# nrf54h20_enga_application register map
Vendor: Nordic Semiconductor; Series: nRF54h; File version: 1
CPU: CM33 r0p4, little endian, MPU, FPU, 3 interrupt priority bits, 480 interrupts, 4 SAU regions
Registers are 32-bit, read-write, reset 0x0 unless marked. A register's access mark holds for its fields unless they carry their own. Offsets are from the block's base; [hi:lo] are bit positions; lines under a group give offsets from that group; {n}, {i} and the like mark numbered series; 'fields as' and 'values as' point back to an identical list.

## UICR_NS — User information configuration registers
Base 0x0FFF8000
{0x0+8i} MEM[{i}] (i=0..15) group — Unspecified
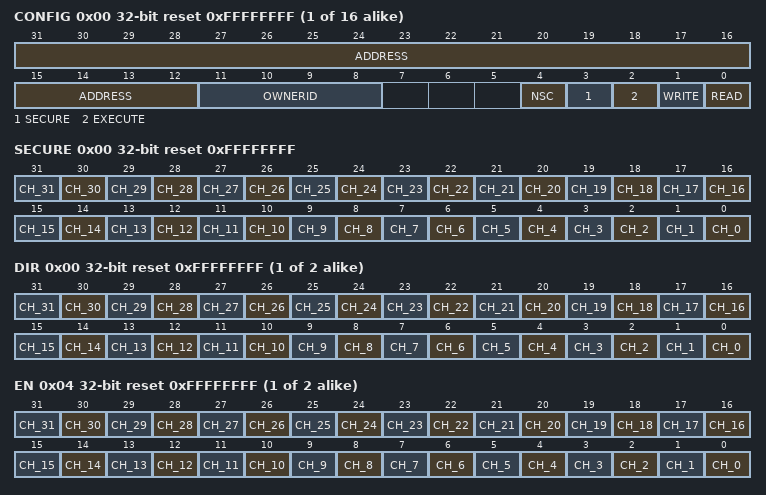
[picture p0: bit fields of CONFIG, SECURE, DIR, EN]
  0x00 CONFIG reset 0xFFFFFFFF — Description cluster: Memory configuration of the memory region
    [31:12] ADDRESS — Memory region start address, bits [31:12]
    [11:8] OWNERID — Memory owner identification
    [4] NSC
      1=Disabled (Memory region is not non-secure callable); 0=Enabled (Memory region is non-secure callable)
    [3] SECURE
      1=Secure (Non-secure access to MEM[n] is not allowed); 0=Non-secure access to MEM[n] is allowed
    [2] EXECUTE
      1=NotAllowed (SW execution from MEM[n] is not allowed); 0=Allowed (SW execution from MEM[n] is allowed)
    [1] WRITE
      1=NotAllowed (Write access to MEM[n] is not allowed); 0=Allowed (Write access to MEM[n] is allowed)
    [0] READ
      1=NotAllowed (Read access to MEM[n] is not allowed); 0=Allowed (Read access to MEM[n] is allowed)
  0x04 SIZE reset 0xFFFFFFFF — Description cluster: Size of the memory region
    [31:0] SIZE — Memory size in bytes
{0x100+4i} PERIPH[{i}] (i=0..191) group — Unspecified
  0x00 CONFIG reset 0xFFFFFFFF — Description cluster: Peripheral configuration
    [31:12] ADDRESS — Peripheral address, bits [31:12]
    [11:8] PROCESSOR — Processor ID of the processor that will receive the peripheral IRQ
    [5] DMASEC — Security attribution for the DMA transfer
      1=Secure (DMA transfers initiated by this peripheral have the secure attribute set); 0=NonSecure (DMA transfers initiated by this peripheral have the non-secure attribute set)
    [3] SECURE — Peripheral security mapping
      1=Secure (Peripheral is mapped in secure peripheral address space); 0=NonSecure (Peripheral is mapped in non-secure peripheral address space.)
{0x480+0xC*i} GPIOTE[{i}] (i=0..3) group — Unspecified
  0x00 INSTANCE reset 0xFFFFFFFF — Description cluster: Address of the GPIOTE instance associated with GPIOTE[n]
    [31:0] ADDRESS — Instance address
  0x04 CH group — Unspecified
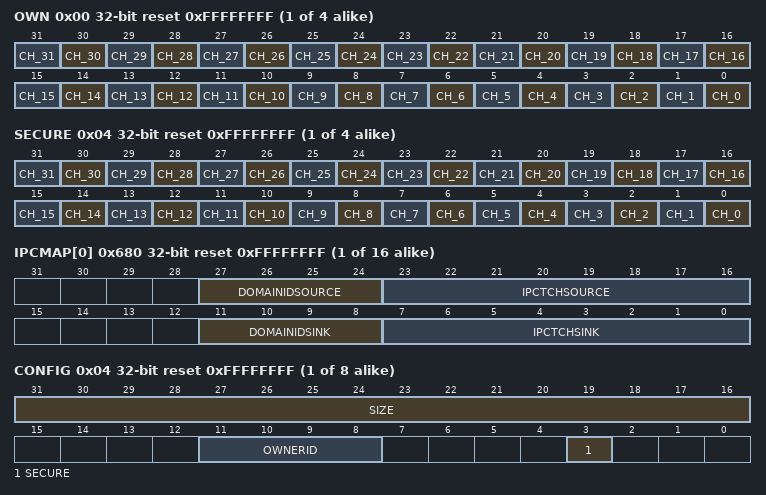
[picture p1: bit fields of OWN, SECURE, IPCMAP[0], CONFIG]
    0x00 OWN reset 0xFFFFFFFF — Description cluster: Request ownership of the channels of GPIOTE[n]
      [n] CH_{n} (n=0..31) — Channel number
        1=NotOwn (Do not own the channel {n}); 0=Own (Own the channel {n})
    0x04 SECURE reset 0xFFFFFFFF — Description cluster: Request permission for the channels of GPIOTE[n]
      [n] CH_{n} (n=0..31) — Channel number
        1=Secure (The channel {n} is secure); 0=NonSecure (The channel {n} is non-secure)
0x4B0 IPCT group — Unspecified
  0x00 LOCAL group — Unspecified
    0x00 CH group — Unspecified
      0x00 SECURE reset 0xFFFFFFFF — Request permission for the channels of IPCT in the local domain
        fields as GPIOTE[0].CH.SECURE
    0x04 INTERRUPT group — Unspecified
      0x00 SECURE reset 0xFFFFFFFF — Request permission for the interrupts of IPCT in the local domain
        [n] INT_{n} (n=0..31) — Interrupt number
          1=Secure (The interrupt {n} is secure); 0=NonSecure (The interrupt {n} is non-secure)
  {0x8+0x14*j} GLOBAL[{j}] (j=0..1) group — Unspecified
    0x00 INSTANCE reset 0xFFFFFFFF — Description cluster: Address of the IPCT instance associated with IPCT[n].GLOBAL
      [31:0] ADDRESS — Instance address
    0x04 CH group — Unspecified
      0x00 OWN reset 0xFFFFFFFF — Description cluster: Request ownership of the channels of IPCT[n] in Global domain
        fields as GPIOTE[0].CH.OWN
      0x04 SECURE reset 0xFFFFFFFF — Description cluster: Request permission for the channels of IPCT[n] in Global domain
        fields as GPIOTE[0].CH.SECURE
    0x0C INTERRUPT group — Unspecified
      0x00 OWN reset 0xFFFFFFFF — Description cluster: Request ownership of the interrupts of IPCT[n] in Global domain
        [n] INT_{n} (n=0..31) — Interrupt number
          1=NotOwn (Do not own the interrupt {n}); 0=Own (Own the interrupt {n})
      0x04 SECURE reset 0xFFFFFFFF — Description cluster: Request permission for the interrupts of IPCT[n] in Global domain
        fields as IPCT.LOCAL.INTERRUPT.SECURE
0x4E0 DPPI group — Unspecified
  {0x0+0x14*j} LOCAL[{j}] (j=0..1) group — Unspecified
    0x00 INSTANCE reset 0xFFFFFFFF — Description cluster: Address of the DPPI instance associated with DPPI[n].LOCAL
      [31:0] ADDRESS — Instance address
    0x04 CH group — Unspecified
      0x00 SECURE reset 0xFFFFFFFF — Description cluster: Request permission for the channels of DPPI[n] in the local domain
        fields as GPIOTE[0].CH.SECURE
      0x04 LINK group — Unspecified
        0x00 DIR reset 0xFFFFFFFF — Description cluster: Request linking the channels of DPPI[n] in local domain as source or sink
          [n] CH_{n} (n=0..31) — Link direction
            1=Source (The channel {n} is linked as source); 0=Sink (The channel {n} is linked as sink)
        0x04 EN reset 0xFFFFFFFF — Description cluster: Request linking of the channels of DPPI[n] in the local domain
          [n] CH_{n} (n=0..31) — Link enable
            1=Disabled (The channel {n} is disabled); 0=Enabled (The channel {n} is enabled)
    0x10 CHG group — Unspecified
      0x00 SECURE reset 0xFFFFFFFF — Description cluster: Request permission for the channel groups of DPPI[n] in the local domain
        [n] CHG_{n} (n=0..31) — Channel group number
          1=Secure (The channel group {n} is secure); 0=NonSecure (The channel group {n} is non-secure)
  {0x28+0x1C*j} GLOBAL[{j}] (j=0..11) group — Unspecified
    0x00 INSTANCE reset 0xFFFFFFFF — Description cluster: Address of the DPPI instance associated with DPPI[n].GLOBAL
      [31:0] ADDRESS — Instance address
    0x04 CH group — Unspecified
      0x00 OWN reset 0xFFFFFFFF — Description cluster: Request ownership of the channels of DPPI[n] in Global Domain
        fields as GPIOTE[0].CH.OWN
      0x04 SECURE reset 0xFFFFFFFF — Description cluster: Request permission for the channels of DPPI[n] in Global domain
        fields as GPIOTE[0].CH.SECURE
      0x08 LINK group — Unspecified
        0x00 DIR reset 0xFFFFFFFF — Description cluster: Request linking the channels of DPPI[n] in Global domain as source or sink
          fields as DPPI.LOCAL[0].CH.LINK.DIR
        0x04 EN reset 0xFFFFFFFF — Description cluster: Request linking of the channels of DPPI[n] in the Global domain
          fields as DPPI.LOCAL[0].CH.LINK.EN
    0x14 CHG group — Unspecified
      0x00 OWN reset 0xFFFFFFFF — Description cluster: Request ownership of the channel groups of DPPI[n] in Global domain
        [n] CHG_{n} (n=0..31) — Channel group number
          1=NotOwn (Do not own the channel group {n}); 0=Own (Own the channel group {n})
      0x04 SECURE reset 0xFFFFFFFF — Description cluster: Request permission for the channel groups of DPPI[n] in Global domain
        fields as DPPI.LOCAL[0].CHG.SECURE
0x660 GRTC group — Unspecified
  0x00 CC group — Unspecified
    0x00 OWN reset 0xFFFFFFFF — Request ownership of the CCs of GRTCGRTC
      [n] CC_{n} (n=0..15) — Capture/compare register number
        1=NotOwn (Do not own the CC register {n}); 0=Own (Own the CC register {n})
    0x04 SECURE reset 0xFFFFFFFF — Request permission for the CCs of GRTC
      [n] CC_{n} (n=0..15) — Capture/compare register number
        1=Secure (The CC register {n} is secure); 0=NonSecure (The CC register {n} is non-secure)
{0x680+4i} IPCMAP[{i}] (i=0..15) reset 0xFFFFFFFF — Description collection: Request configuration for the channel n of IPCMAP
  [27:24] DOMAINIDSOURCE — Domain ID (source side)
  [23:16] IPCTCHSOURCE — IPCT channel number (source side)
  [11:8] DOMAINIDSINK — Domain ID (sink side)
  [7:0] IPCTCHSINK — IPCT channel number (sink side)
{0x700+8i} MAILBOX[{i}] (i=0..7) group — Unspecified
  0x00 ADDRESS reset 0xFFFFFFFF — Description cluster: Memory start address of mailbox n
    [31:0] ADDRESS — Memory address
  0x04 CONFIG reset 0xFFFFFFFF — Description cluster: Configuration of mailbox n
    [31:16] SIZE — Memory size
    [11:8] OWNERID — Remote owner identification
    [3] SECURE — Permission
      1=Secure (The mailbox memory is secure); 0=NonSecure (The mailbox memory is non-secure)
0x740 TRACE group — Unspecified
  0x00 ETBSINK group — Unspecified
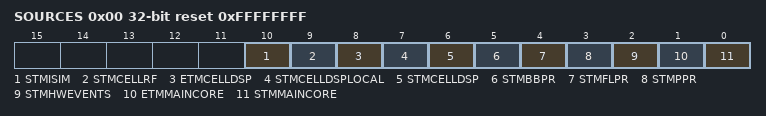
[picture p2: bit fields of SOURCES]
    0x00 SOURCES reset 0xFFFFFFFF — Unspecified
      [all] fields
        1=NotRequested; 0=Requested
      [10] STMISIM — STM trace from iSIM secure core
      [9] STMCELLRF — STM trace from Cellular RF CPU
      [8] ETMCELLDSP — ETM trace from Cellular DSP
      [7] STMCELLDSPLOCAL — STM trace from Cellular DSP local STM
      [6] STMCELLDSP — STM trace from Cellular DSP
      [5] STMBBPR — STM trace from BBPR CPU
      [4] STMFLPR — STM trace from FLPR CPU
      [3] STMPPR — STM trace from PPR CPU
      [2] STMHWEVENTS — STM HW events trace
      [1] ETMMAINCORE — ETM trace from the domain main CPU
      [0] STMMAINCORE — STM trace from the domain main CPU
  0x04 TPIUSINK group — Unspecified
    0x00 SOURCES reset 0xFFFFFFFF — Unspecified
      fields as TRACE.ETBSINK.SOURCES
  0x08 ETRSINK group — Unspecified
    0x00 SOURCES reset 0xFFFFFFFF — Unspecified
      fields as TRACE.ETBSINK.SOURCES
  0x0C PORTCONFIG reset 0xFFFFFFFF — Trace port speed configuration
    [1:0] PORTCONFIG
      3=FullSpeed; 2=HalfSpeed; 1=QuarterSpeed (One quarter speed); 0=EightSpeed (One eigth speed)
0x780 INITSVTOR reset 0xFFFFFFFF — Initial value of the secure VTOR (Vector Table Offset Register) after CPU reset.
  [31:0] INITSVTOR — Initial value of the VTOR.
0x784 INITNSVTOR reset 0xFFFFFFFF — Initial value of the non-secure VTOR (Vector Table Offset Register).
  [31:0] INITNSVTOR — Initial value of the VTOR.
0x7FC PTREXTUICR reset 0xFFFFFFFF — Pointer to extended UICR.

## Notices in the file
Copyright (c) 2010 - 2024, Nordic Semiconductor ASA
All rights reserved.
Redistribution and use in source and binary forms, with or without modification,
are permitted provided that the following conditions are met:
1. Redistributions of source code must retain the above copyright notice, this
list of conditions and the following disclaimer.
2. Redistributions in binary form, except as embedded into a Nordic
Semiconductor ASA integrated circuit in a product or a software update for
such product, must reproduce the above copyright notice, this list of
conditions and the following disclaimer in the documentation and/or other
materials provided with the distribution.
3. Neither the name of Nordic Semiconductor ASA nor the names of its
contributors may be used to endorse or promote products derived from this
software without specific prior written permission.
4. This software, with or without modification, must only be used with a
Nordic Semiconductor ASA integrated circuit.
5. Any software provided in binary form under this license must not be reverse
engineered, decompiled, modified and/or disassembled.
THIS SOFTWARE IS PROVIDED BY NORDIC SEMICONDUCTOR ASA "AS IS" AND ANY EXPRESS
OR IMPLIED WARRANTIES, INCLUDING, BUT NOT LIMITED TO, THE IMPLIED WARRANTIES
OF MERCHANTABILITY, NONINFRINGEMENT, AND FITNESS FOR A PARTICULAR PURPOSE ARE
DISCLAIMED. IN NO EVENT SHALL NORDIC SEMICONDUCTOR ASA OR CONTRIBUTORS BE
LIABLE FOR ANY DIRECT, INDIRECT, INCIDENTAL, SPECIAL, EXEMPLARY, OR
CONSEQUENTIAL DAMAGES (INCLUDING, BUT NOT LIMITED TO, PROCUREMENT OF SUBSTITUTE
GOODS OR SERVICES; LOSS OF USE, DATA, OR PROFITS; OR BUSINESS INTERRUPTION)
HOWEVER CAUSED AND ON ANY THEORY OF LIABILITY, WHETHER IN CONTRACT, STRICT
LIABILITY, OR TORT (INCLUDING NEGLIGENCE OR OTHERWISE) ARISING IN ANY WAY OUT
OF THE USE OF THIS SOFTWARE, EVEN IF ADVISED OF THE POSSIBILITY OF SUCH DAMAGE.
